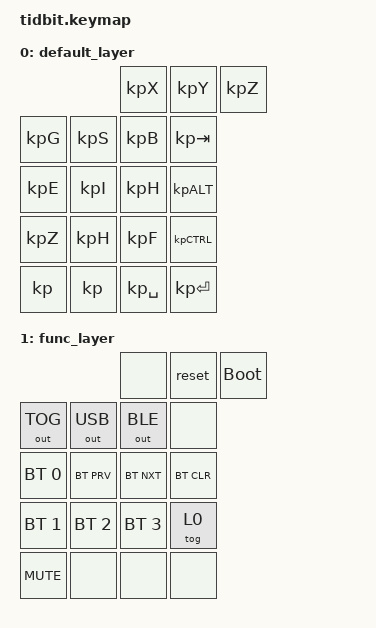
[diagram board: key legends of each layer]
/*
 * Copyright (c) 2020 The ZMK Contributors
 *
 * SPDX-License-Identifier: MIT
 */

#include <behaviors.dtsi>
#include <dt-bindings/zmk/bt.h>
#include <dt-bindings/zmk/outputs.h>
#include <dt-bindings/zmk/keys.h>

&encoder_1_top_row {
	status = "okay";
};

/ {
	sensors {
		compatible = "zmk,keymap-sensors";
		sensors = <&encoder_1_top_row>;
	};

	keymap {
		compatible = "zmk,keymap";
		
		default_layer {
			bindings = <
								&kp KP_X  &kp KP_Y &kp KP_Z
				&kp KP_G &kp KP_S &kp KP_B &kp KP_TAB
				&kp KP_E &kp KP_I &kp KP_H &kp KP_ALT
				&kp KP_Z &kp KP_H &kp KP_F &kp KP_CTRL
				&kp  &kp  &kp KP_SPACE  &kp KP_ENTER
			>;

			sensor-bindings = <&inc_dec_kp C_VOLUME_UP C_VOLUME_DOWN>;
		};

		 func_layer {
			 bindings = <
								&none           &reset          &bootloader
				&out OUT_TOG    &out OUT_USB    &out OUT_BLE    &none
				&bt BT_SEL 0    &bt BT_PRV      &bt BT_NXT      &bt BT_CLR
				&bt BT_SEL 1    &bt BT_SEL 2    &bt BT_SEL 3    &tog 0
				&kp C_MUTE      &none           &none           &none
			 >;

			 sensor-bindings = <&inc_dec_kp C_VOLUME_UP C_VOLUME_DOWN>;
		 };
	};
};
